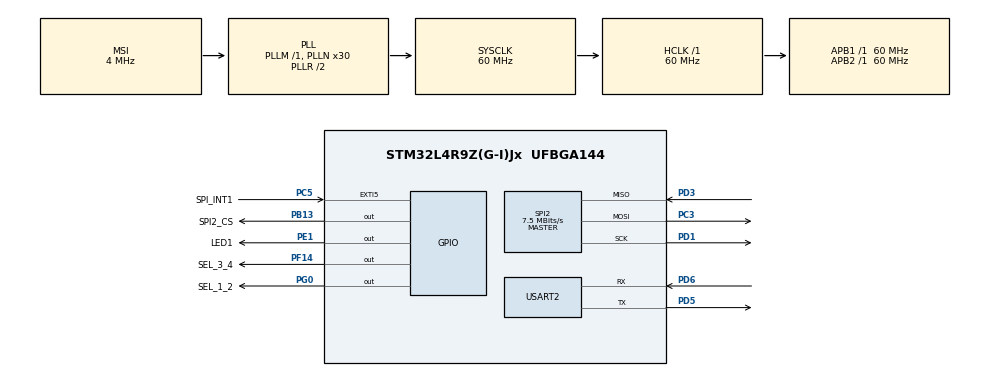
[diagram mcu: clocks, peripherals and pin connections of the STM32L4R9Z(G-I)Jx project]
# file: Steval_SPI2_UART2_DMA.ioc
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Dma.Request0=SPI2_RX
Dma.SPI2_RX.0.Direction=DMA_PERIPH_TO_MEMORY
Dma.SPI2_RX.0.EventEnable=DISABLE
Dma.SPI2_RX.0.Instance=DMA1_Channel1
Dma.SPI2_RX.0.MemDataAlignment=DMA_MDATAALIGN_BYTE
Dma.SPI2_RX.0.MemInc=DMA_MINC_ENABLE
Dma.SPI2_RX.0.Mode=DMA_CIRCULAR
Dma.SPI2_RX.0.PeriphDataAlignment=DMA_PDATAALIGN_BYTE
Dma.SPI2_RX.0.PeriphInc=DMA_PINC_DISABLE
Dma.SPI2_RX.0.Polarity=HAL_DMAMUX_REQUEST_GEN_RISING
Dma.SPI2_RX.0.Priority=DMA_PRIORITY_LOW
Dma.SPI2_RX.0.RequestNumber=1
Dma.SPI2_RX.0.SignalID=NONE
Dma.SPI2_RX.0.SyncEnable=DISABLE
Dma.SPI2_RX.0.SyncPolarity=HAL_DMAMUX_SYNC_NO_EVENT
Dma.SPI2_RX.0.SyncRequestNumber=1
Dma.SPI2_RX.0.SyncSignalID=NONE
Mcu.Family=STM32L4
Mcu.Name=STM32L4R9Z(G-I)Jx
Mcu.Package=UFBGA144
NVIC.DMA1_Channel1_IRQn=true\:0\:0\:false\:false\:true\:false\:true
NVIC.EXTI9_5_IRQn=true\:0\:0\:false\:false\:true\:true\:true
NVIC.PriorityGroup=NVIC_PRIORITYGROUP_4
NVIC.TIM1_TRG_COM_TIM17_IRQn=true\:0\:0\:false\:false\:true\:true\:true
PB13.GPIO_Label=SPI2_CS
PB13.PinState=GPIO_PIN_SET
PB13.Signal=GPIO_Output
PC3.Mode=Full_Duplex_Master
PC3.Signal=SPI2_MOSI
PC5.GPIO_Label=SPI_INT1
PC5.Signal=GPXTI5
PD1.Mode=Full_Duplex_Master
PD1.Signal=SPI2_SCK
PD3.Mode=Full_Duplex_Master
PD3.Signal=SPI2_MISO
PD5.Mode=Asynchronous
PD5.Signal=USART2_TX
PD6.Mode=Asynchronous
PD6.Signal=USART2_RX
PE1.GPIO_Label=LED1
PE1.Signal=GPIO_Output
PF14.GPIO_Label=SEL_3_4
PF14.PinState=GPIO_PIN_SET
PF14.Signal=GPIO_Output
PG0.GPIO_Label=SEL_1_2
PG0.PinState=GPIO_PIN_RESET
PG0.Signal=GPIO_Output
ProjectManager.HeapSize=0x200
ProjectManager.StackSize=0x400
ProjectManager.TargetToolchain=STM32CubeIDE
RCC.ADCFreq_Value=19200000
RCC.AHBFreq_Value=60000000
RCC.APB1Freq_Value=60000000
RCC.APB1TimFreq_Value=60000000
RCC.APB2Freq_Value=60000000
RCC.APB2TimFreq_Value=60000000
RCC.CK48CLockSelection=RCC_USBCLKSOURCE_HSI48
RCC.CortexFreq_Value=60000000
RCC.DSITX_Div=1
RCC.HCLKFreq_Value=60000000
RCC.HSE_VALUE=16000000
RCC.HSI48_VALUE=48000000
RCC.HSI_VALUE=16000000
RCC.LSE_VALUE=32768
RCC.MSI_VALUE=4000000
RCC.PLLDSIODF=DSI_PLL_OUT_DIV2
RCC.PLLM2=5
RCC.PLLM3=2
RCC.PLLN=30
RCC.PLLSAI1N=96
RCC.PLLSAI1P=RCC_PLLP_DIV25
RCC.PLLSAI1Q=RCC_PLLQ_DIV4
RCC.PLLSAI1R=RCC_PLLR_DIV4
RCC.RTCClockSelection=RCC_RTCCLKSOURCE_LSE
RCC.SDMMCClockSelection=RCC_SDIOCLKSOURCE_CLK48
RCC.SYSCLKFreq_VALUE=60000000
RCC.SYSCLKSource=RCC_SYSCLKSOURCE_PLLCLK
RCC.USBFreq_Value=48000000
RCC.VCOOutputFreq_Value=120000000
SPI2.BaudRatePrescaler=SPI_BAUDRATEPRESCALER_8
SPI2.CLKPhase=SPI_PHASE_2EDGE
SPI2.CLKPolarity=SPI_POLARITY_HIGH
SPI2.CalculateBaudRate=7.5 MBits/s
SPI2.DataSize=SPI_DATASIZE_8BIT
SPI2.Direction=SPI_DIRECTION_2LINES
SPI2.Mode=SPI_MODE_MASTER
SPI2.VirtualType=VM_MASTER
TIM17.Period=1000
TIM17.Prescaler=6-1
USART2.VirtualMode-Asynchronous=VM_ASYNC
VP_TIM17_VS_ClockSourceINT.Mode=Enable_Timer
board=STEVAL-STWINKT1B

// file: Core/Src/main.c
/* USER CODE BEGIN Header */
/**
  ******************************************************************************
  * @file           : main.c
  * @brief          : Main program body
  ******************************************************************************
  * @attention
  *
  * <h2><center>&copy; Copyright (c) 2021 STMicroelectronics.
  * All rights reserved.</center></h2>
  *
  * This software component is licensed by ST under BSD 3-Clause license,
  * the "License"; You may not use this file except in compliance with the
  * License. You may obtain a copy of the License at:
  *                        opensource.org/licenses/BSD-3-Clause
  *
  ******************************************************************************
  */
/* USER CODE END Header */
#include "main.h"

SPI_HandleTypeDef hspi2;
DMA_HandleTypeDef hdma_spi2_rx;

TIM_HandleTypeDef htim17;

UART_HandleTypeDef huart2;

/* USER CODE BEGIN PV */
bool int1_flag = 0;
/* USER CODE END PV */

void SystemClock_Config(void);
static void MX_GPIO_Init(void);
static void MX_USART2_UART_Init(void);
static void MX_SPI2_Init(void);
static void MX_DMA_Init(void);
static void MX_TIM17_Init(void);

int main(void)
{

  /* MCU Configuration--------------------------------------------------------*/

  /* Reset of all peripherals, Initializes the Flash interface and the Systick. */
  HAL_Init();

  /* Configure the system clock */
  SystemClock_Config();

  /* Initialize all configured peripherals */
  MX_GPIO_Init();
  MX_USART2_UART_Init();
  MX_SPI2_Init();
  MX_DMA_Init();
  MX_TIM17_Init();
  /* USER CODE BEGIN 2 */
  HAL_TIM_Base_Start_IT(&htim17);
  IIS3DWB_INIT(hspi2, SPI2_CS_GPIO_Port , SPI2_CS_Pin);
  /* USER CODE END 2 */

  /* Infinite loop */
  /* USER CODE BEGIN WHILE */
  while (1)
  {
	  //IIS3DWB_MEASSURE();

	  //HAL_GPIO_TogglePin(LED1_GPIO_Port , LED1_Pin );
	  //char wakeUp [] = {"MCU "};
	  //HAL_UART_Transmit(&huart2, (uint8_t *) wakeUp, sizeof(wakeUp), HAL_MAX_DELAY);
	  //HAL_Delay(500);
	  //checkStatus();
	  if(int1_flag){
		  IIS3DWB_Int_Measure();
		  int1_flag = 0;
	  }

    /* USER CODE END WHILE */

  }
}

void SystemClock_Config(void)
{
  RCC_OscInitTypeDef RCC_OscInitStruct = {0};
  RCC_ClkInitTypeDef RCC_ClkInitStruct = {0};

  /** Configure the main internal regulator output voltage
  */
  if (HAL_PWREx_ControlVoltageScaling(PWR_REGULATOR_VOLTAGE_SCALE1) != HAL_OK)
  {
    Error_Handler();
  }
  /** Initializes the RCC Oscillators according to the specified parameters
  * in the RCC_OscInitTypeDef structure.
  */
  RCC_OscInitStruct.OscillatorType = RCC_OSCILLATORTYPE_MSI;
  RCC_OscInitStruct.MSIState = RCC_MSI_ON;
  RCC_OscInitStruct.MSICalibrationValue = 0;
  RCC_OscInitStruct.MSIClockRange = RCC_MSIRANGE_6;
  RCC_OscInitStruct.PLL.PLLState = RCC_PLL_ON;
  RCC_OscInitStruct.PLL.PLLSource = RCC_PLLSOURCE_MSI;
  RCC_OscInitStruct.PLL.PLLM = 1;
  RCC_OscInitStruct.PLL.PLLN = 30;
  RCC_OscInitStruct.PLL.PLLP = RCC_PLLP_DIV2;
  RCC_OscInitStruct.PLL.PLLQ = RCC_PLLQ_DIV2;
  RCC_OscInitStruct.PLL.PLLR = RCC_PLLR_DIV2;
  if (HAL_RCC_OscConfig(&RCC_OscInitStruct) != HAL_OK)
  {
    Error_Handler();
  }
  /** Initializes the CPU, AHB and APB buses clocks
  */
  RCC_ClkInitStruct.ClockType = RCC_CLOCKTYPE_HCLK|RCC_CLOCKTYPE_SYSCLK
                              |RCC_CLOCKTYPE_PCLK1|RCC_CLOCKTYPE_PCLK2;
  RCC_ClkInitStruct.SYSCLKSource = RCC_SYSCLKSOURCE_PLLCLK;
  RCC_ClkInitStruct.AHBCLKDivider = RCC_SYSCLK_DIV1;
  RCC_ClkInitStruct.APB1CLKDivider = RCC_HCLK_DIV1;
  RCC_ClkInitStruct.APB2CLKDivider = RCC_HCLK_DIV1;

  if (HAL_RCC_ClockConfig(&RCC_ClkInitStruct, FLASH_LATENCY_2) != HAL_OK)
  {
    Error_Handler();
  }
}

static void MX_SPI2_Init(void)
{

  /* SPI2 parameter configuration*/
  hspi2.Instance = SPI2;
  hspi2.Init.Mode = SPI_MODE_MASTER;
  hspi2.Init.Direction = SPI_DIRECTION_2LINES;
  hspi2.Init.DataSize = SPI_DATASIZE_8BIT;
  hspi2.Init.CLKPolarity = SPI_POLARITY_HIGH;
  hspi2.Init.CLKPhase = SPI_PHASE_2EDGE;
  hspi2.Init.NSS = SPI_NSS_SOFT;
  hspi2.Init.BaudRatePrescaler = SPI_BAUDRATEPRESCALER_8;
  hspi2.Init.FirstBit = SPI_FIRSTBIT_MSB;
  hspi2.Init.TIMode = SPI_TIMODE_DISABLE;
  hspi2.Init.CRCCalculation = SPI_CRCCALCULATION_DISABLE;
  hspi2.Init.CRCPolynomial = 7;
  hspi2.Init.CRCLength = SPI_CRC_LENGTH_DATASIZE;
  hspi2.Init.NSSPMode = SPI_NSS_PULSE_DISABLE;
  if (HAL_SPI_Init(&hspi2) != HAL_OK)
  {
    Error_Handler();
  }

}

static void MX_TIM17_Init(void)
{

  htim17.Instance = TIM17;
  htim17.Init.Prescaler = 6-1;
  htim17.Init.CounterMode = TIM_COUNTERMODE_UP;
  htim17.Init.Period = 1000;
  htim17.Init.ClockDivision = TIM_CLOCKDIVISION_DIV1;
  htim17.Init.RepetitionCounter = 0;
  htim17.Init.AutoReloadPreload = TIM_AUTORELOAD_PRELOAD_DISABLE;
  if (HAL_TIM_Base_Init(&htim17) != HAL_OK)
  {
    Error_Handler();
  }

}

static void MX_USART2_UART_Init(void)
{

  huart2.Instance = USART2;
  huart2.Init.BaudRate = 115200;
  huart2.Init.WordLength = UART_WORDLENGTH_8B;
  huart2.Init.StopBits = UART_STOPBITS_1;
  huart2.Init.Parity = UART_PARITY_NONE;
  huart2.Init.Mode = UART_MODE_TX_RX;
  huart2.Init.HwFlowCtl = UART_HWCONTROL_NONE;
  huart2.Init.OverSampling = UART_OVERSAMPLING_16;
  huart2.Init.OneBitSampling = UART_ONE_BIT_SAMPLE_DISABLE;
  huart2.Init.ClockPrescaler = UART_PRESCALER_DIV1;
  huart2.AdvancedInit.AdvFeatureInit = UART_ADVFEATURE_NO_INIT;
  if (HAL_UART_Init(&huart2) != HAL_OK)
  {
    Error_Handler();
  }
  if (HAL_UARTEx_SetTxFifoThreshold(&huart2, UART_TXFIFO_THRESHOLD_1_8) != HAL_OK)
  {
    Error_Handler();
  }
  if (HAL_UARTEx_SetRxFifoThreshold(&huart2, UART_RXFIFO_THRESHOLD_1_8) != HAL_OK)
  {
    Error_Handler();
  }
  if (HAL_UARTEx_DisableFifoMode(&huart2) != HAL_OK)
  {
    Error_Handler();
  }

}

static void MX_DMA_Init(void)
{

  /* DMA controller clock enable */
  __HAL_RCC_DMAMUX1_CLK_ENABLE();
  __HAL_RCC_DMA1_CLK_ENABLE();

  /* DMA interrupt init */
  /* DMA1_Channel1_IRQn interrupt configuration */
  HAL_NVIC_SetPriority(DMA1_Channel1_IRQn, 0, 0);
  HAL_NVIC_EnableIRQ(DMA1_Channel1_IRQn);

}

static void MX_GPIO_Init(void)
{
  GPIO_InitTypeDef GPIO_InitStruct = {0};

  /* GPIO Ports Clock Enable */
  __HAL_RCC_GPIOD_CLK_ENABLE();
  __HAL_RCC_GPIOE_CLK_ENABLE();
  __HAL_RCC_GPIOC_CLK_ENABLE();
  __HAL_RCC_GPIOG_CLK_ENABLE();
  __HAL_RCC_GPIOF_CLK_ENABLE();
  __HAL_RCC_GPIOB_CLK_ENABLE();

  /*Configure GPIO pin Output Level */
  HAL_GPIO_WritePin(LED1_GPIO_Port, LED1_Pin, GPIO_PIN_RESET);

  /*Configure GPIO pin Output Level */
  HAL_GPIO_WritePin(SEL_1_2_GPIO_Port, SEL_1_2_Pin, GPIO_PIN_RESET);

  /*Configure GPIO pin Output Level */
  HAL_GPIO_WritePin(SEL_3_4_GPIO_Port, SEL_3_4_Pin, GPIO_PIN_SET);

  /*Configure GPIO pin Output Level */
  HAL_GPIO_WritePin(SPI2_CS_GPIO_Port, SPI2_CS_Pin, GPIO_PIN_SET);

  /*Configure GPIO pin : LED1_Pin */
  GPIO_InitStruct.Pin = LED1_Pin;
  GPIO_InitStruct.Mode = GPIO_MODE_OUTPUT_PP;
  GPIO_InitStruct.Pull = GPIO_NOPULL;
  GPIO_InitStruct.Speed = GPIO_SPEED_FREQ_LOW;
  HAL_GPIO_Init(LED1_GPIO_Port, &GPIO_InitStruct);

  /*Configure GPIO pin : SPI_INT1_Pin */
  GPIO_InitStruct.Pin = SPI_INT1_Pin;
  GPIO_InitStruct.Mode = GPIO_MODE_IT_RISING;
  GPIO_InitStruct.Pull = GPIO_NOPULL;
  HAL_GPIO_Init(SPI_INT1_GPIO_Port, &GPIO_InitStruct);

  /*Configure GPIO pin : SEL_1_2_Pin */
  GPIO_InitStruct.Pin = SEL_1_2_Pin;
  GPIO_InitStruct.Mode = GPIO_MODE_OUTPUT_PP;
  GPIO_InitStruct.Pull = GPIO_NOPULL;
  GPIO_InitStruct.Speed = GPIO_SPEED_FREQ_LOW;
  HAL_GPIO_Init(SEL_1_2_GPIO_Port, &GPIO_InitStruct);

  /*Configure GPIO pin : SEL_3_4_Pin */
  GPIO_InitStruct.Pin = SEL_3_4_Pin;
  GPIO_InitStruct.Mode = GPIO_MODE_OUTPUT_PP;
  GPIO_InitStruct.Pull = GPIO_NOPULL;
  GPIO_InitStruct.Speed = GPIO_SPEED_FREQ_LOW;
  HAL_GPIO_Init(SEL_3_4_GPIO_Port, &GPIO_InitStruct);

  /*Configure GPIO pin : SPI2_CS_Pin */
  GPIO_InitStruct.Pin = SPI2_CS_Pin;
  GPIO_InitStruct.Mode = GPIO_MODE_OUTPUT_PP;
  GPIO_InitStruct.Pull = GPIO_NOPULL;
  GPIO_InitStruct.Speed = GPIO_SPEED_FREQ_LOW;
  HAL_GPIO_Init(SPI2_CS_GPIO_Port, &GPIO_InitStruct);

  /* EXTI interrupt init*/
  HAL_NVIC_SetPriority(EXTI9_5_IRQn, 0, 0);
//  HAL_NVIC_EnableIRQ(EXTI9_5_IRQn);

}

/* USER CODE BEGIN 4 */

//Callback: timer has reset
void HAL_TIM_PeriodElapsedCallback(TIM_HandleTypeDef *htim){

	//Check which version of the timer triggered this callback
	if(htim==&htim17){

	}
}

void HAL_GPIO_EXTI_Callback(uint16_t GPIO_Pin){
	if(GPIO_Pin==SPI_INT1_Pin){
		//HAL_GPIO_TogglePin(LED1_GPIO_Port , LED1_Pin );
		//HAL_GPIO_WritePin(LED1_GPIO_Port, LED1_Pin, GPIO_PIN_SET);
		//HAL_UART_Transmit(&huart2, (uint8_t*)msg_0, sizeof(msg_0), HAL_MAX_DELAY);
		//IIS3DWB_MEASSURE();
		//IIS3DWB_Int_Measure();
		int1_flag = 1;
	}
}
/* USER CODE END 4 */

void Error_Handler(void)
{
  __disable_irq();
  while (1)
  {
  }
}
